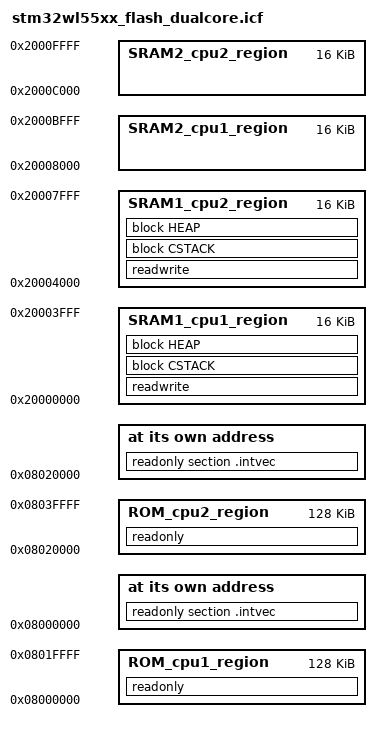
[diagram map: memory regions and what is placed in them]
/*###ICF### Section handled by ICF editor, don't touch! ****/
/*-Editor annotation file-*/
/* IcfEditorFile="$TOOLKIT_DIR$\config\ide\IcfEditor\cortex_v1_0.xml" */
/*-Specials-*/
define symbol __intvec_cpu1_start__ = 0x08000000 ;
define symbol __intvec_cpu2_start__ = 0x08020000 ;

/*-Memory Regions-*/
/***** FLASH Part dedicated to cpu1 *****/
define symbol __region_ROM_cpu1_start__ = 0x08000000;
define symbol __region_ROM_cpu1_end__   = 0x0801FFFF;
/***** FLASH Part dedicated to cpu2 *****/
define symbol __region_ROM_cpu2_start__ = 0x08020000;
define symbol __region_ROM_cpu2_end__   = 0x0803FFFF;

/***** SRAM1 dedicated to cpu1 *****/
define symbol __region_SRAM1_cpu1_start__  = 0x20000000;
define symbol __region_SRAM1_cpu1_end__    = 0x20003FFF;
/***** SRAM1 dedicated to cpu2 *****/
define symbol __region_SRAM1_cpu2_start__  = 0x20004000;
define symbol __region_SRAM1_cpu2_end__    = 0x20007FFF;

/***** SRAM2 dedicated to cpu1 *****/
define symbol __region_SRAM2_cpu1_start__  = 0x20008000;
define symbol __region_SRAM2_cpu1_end__    = 0x2000BFFF;
/***** SRAM2 dedicated to cpu2 *****/
define symbol __region_SRAM2_cpu2_start__  = 0x2000C000;
define symbol __region_SRAM2_cpu2_end__    = 0x2000FFFF;

/*-Sizes-*/
define symbol __size_cstack__ = 0x400;
define symbol __size_heap__   = 0x200;
/**** End of ICF editor section. ###ICF###*/


define memory mem with size = 4G;
define region ROM_cpu1_region   = mem:[from __region_ROM_cpu1_start__ to __region_ROM_cpu1_end__];
define region ROM_cpu2_region   = mem:[from __region_ROM_cpu2_start__ to __region_ROM_cpu2_end__];
define region SRAM1_cpu1_region = mem:[from __region_SRAM1_cpu1_start__ to __region_SRAM1_cpu1_end__];
define region SRAM1_cpu2_region = mem:[from __region_SRAM1_cpu2_start__ to __region_SRAM1_cpu2_end__];
define region SRAM2_cpu1_region = mem:[from __region_SRAM2_cpu1_start__ to __region_SRAM2_cpu1_end__];
define region SRAM2_cpu2_region = mem:[from __region_SRAM2_cpu2_start__ to __region_SRAM2_cpu2_end__];

define block CSTACK    with alignment = 8, size = __size_cstack__   { };
define block HEAP      with alignment = 8, size = __size_heap__     { };

initialize by copy { readwrite };
do not initialize  { section .noinit };

if(CPU==1)
{
place at address mem:__intvec_cpu1_start__ { readonly section .intvec };
place in ROM_cpu1_region   { readonly };
place in SRAM1_cpu1_region   { readwrite, block CSTACK, block HEAP };
}
else
{
place at address mem:__intvec_cpu2_start__ { readonly section .intvec };
place in ROM_cpu2_region   { readonly };
place in SRAM1_cpu2_region   { readwrite, block CSTACK, block HEAP };
}

export symbol __region_ROM_cpu1_start__;
export symbol __region_ROM_cpu1_end__;
export symbol __region_ROM_cpu2_start__;
export symbol __region_ROM_cpu2_end__;
export symbol __region_SRAM1_cpu1_start__;
export symbol __region_SRAM1_cpu1_end__;
export symbol __region_SRAM1_cpu2_start__;
export symbol __region_SRAM1_cpu2_end__;
export symbol __region_SRAM2_cpu1_start__;
export symbol __region_SRAM2_cpu1_end__;
export symbol __region_SRAM2_cpu2_start__;
export symbol __region_SRAM2_cpu2_end__;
